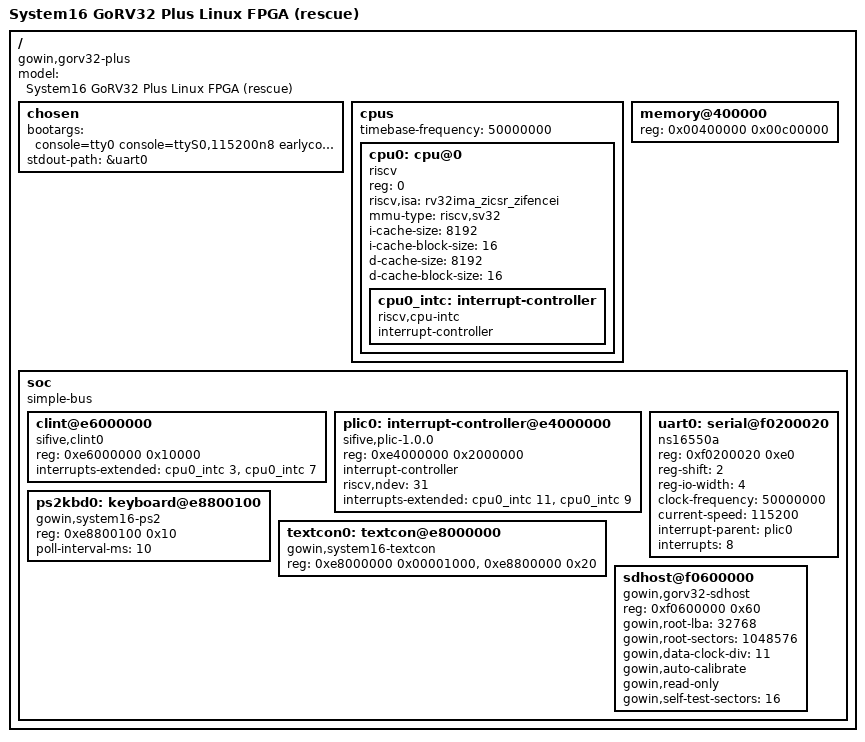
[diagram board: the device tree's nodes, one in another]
/dts-v1/;
/ {
	#address-cells = <1>; #size-cells = <1>;
	compatible = "gowin,gorv32-plus";
	model = "System16 GoRV32 Plus Linux FPGA (rescue)";
	chosen {
		bootargs = "console=tty0 console=ttyS0,115200n8 earlycon=sbi loglevel=7 panic=-1 rdinit=/sbin/init";
		stdout-path = &uart0;
	};
	cpus {
		#address-cells = <1>; #size-cells = <0>;
		timebase-frequency = <50000000>;
		cpu0: cpu@0 {
			compatible = "riscv"; device_type = "cpu"; reg = <0>;
			status = "okay";
			riscv,isa = "rv32ima_zicsr_zifencei";
			mmu-type = "riscv,sv32";
			i-cache-size = <8192>; i-cache-block-size = <16>;
			d-cache-size = <8192>; d-cache-block-size = <16>;
			cpu0_intc: interrupt-controller {
				#interrupt-cells = <1>; interrupt-controller;
				compatible = "riscv,cpu-intc";
			};
		};
	};
	memory@400000 {
		device_type = "memory"; reg = <0x00400000 0x00c00000>;
	};
	soc {
		#address-cells = <1>; #size-cells = <1>;
		compatible = "simple-bus"; ranges;
		clint@e6000000 {
			compatible = "sifive,clint0", "riscv,clint0";
			reg = <0xe6000000 0x10000>;
			interrupts-extended = <&cpu0_intc 3 &cpu0_intc 7>;
		};
		plic0: interrupt-controller@e4000000 {
			compatible = "sifive,plic-1.0.0", "riscv,plic0";
			reg = <0xe4000000 0x2000000>;
			#address-cells = <0>; #interrupt-cells = <1>;
			interrupt-controller; riscv,ndev = <31>;
			interrupts-extended = <&cpu0_intc 11 &cpu0_intc 9>;
		};
		uart0: serial@f0200020 {
			compatible = "ns16550a"; reg = <0xf0200020 0xe0>;
			reg-shift = <2>; reg-io-width = <4>;
			clock-frequency = <50000000>; current-speed = <115200>;
			interrupt-parent = <&plic0>; interrupts = <8>;
			status = "okay";
		};
		ps2kbd0: keyboard@e8800100 {
			compatible = "gowin,system16-ps2";
			reg = <0xe8800100 0x10>;
			poll-interval-ms = <10>;
			status = "okay";
		};
		textcon0: textcon@e8000000 {
			compatible = "gowin,system16-textcon";
			reg = <0xe8000000 0x00001000>, <0xe8800000 0x20>;
			status = "okay";
		};
		sdhost@f0600000 {
			compatible = "gowin,gorv32-sdhost";
			reg = <0xf0600000 0x60>;
			gowin,root-lba = <32768>;
			gowin,root-sectors = <1048576>;
			/* Fallback when calibration is disabled or cannot start. */
			gowin,data-clock-div = <11>;
			/* Test every divider from 25 to 1 MHz in 1- and 4-bit mode.
			 * Only exact, retry-free reads without FIFO-full events pass. */
			gowin,auto-calibrate;
			gowin,read-only;
			/* Printed during probe; no interactive UART command required. */
			gowin,self-test-sectors = <16>;
			status = "okay";
		};
	};
};
